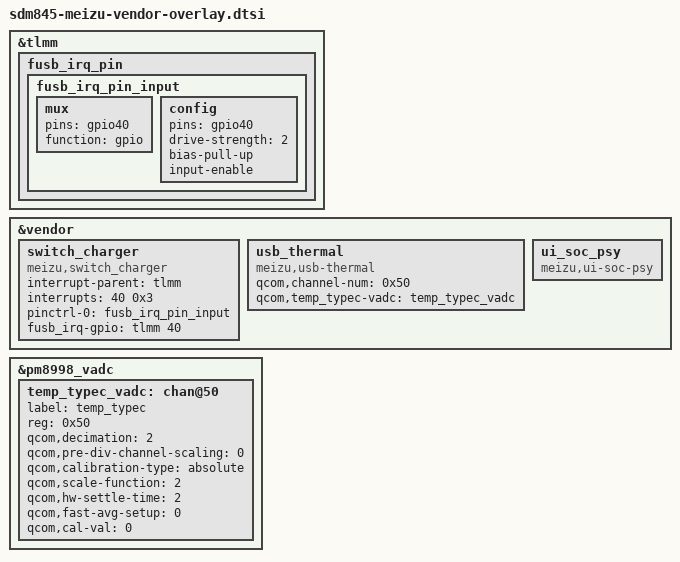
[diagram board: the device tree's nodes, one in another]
/* Copyright (c) 2022, MeizuCustoms enthusiasts
 *
 * This program is free software; you can redistribute it and/or modify
 * it under the terms of the GNU General Public License version 2 and
 * only version 2 as published by the Free Software Foundation.
 *
 * This program is distributed in the hope that it will be useful,
 * but WITHOUT ANY WARRANTY; without even the implied warranty of
 * MERCHANTABILITY or FITNESS FOR A PARTICULAR PURPOSE.  See the
 * GNU General Public License for more details.
 */

&tlmm {
    fusb_irq_pin {
        fusb_irq_pin_input: fusb_irq_pin_input {
            mux {
                pins = "gpio40";
                function = "gpio";
            };

            config {
                pins = "gpio40";
                drive-strength = <2>;
                bias-pull-up;
                input-enable;
            };
        };
    };
};

&vendor {
    switch_charger {
        compatible = "meizu,switch_charger";
        interrupt-parent = <&tlmm>;
        interrupts = <40 0x3>;
        interrupt-names = "fusb_irq";
        pinctrl-0 = <&fusb_irq_pin_input>;
        pinctrl-names = "default";
        fusb_irq-gpio = <&tlmm 40 0x0>;
    };

    usb_thermal {
        compatible = "meizu,usb-thermal";
        qcom,channel-num = <0x50>;
        qcom,temp_typec-vadc = <&temp_typec_vadc>;
    };

    ui_soc_psy {
        compatible = "meizu,ui-soc-psy";
    };
};

&pm8998_vadc {
    temp_typec_vadc: chan@50 {
        label = "temp_typec";
        reg = <0x50>;
        qcom,decimation = <2>;
        qcom,pre-div-channel-scaling = <0>;
        qcom,calibration-type = "absolute";
        qcom,scale-function = <2>;
        qcom,hw-settle-time = <2>;
        qcom,fast-avg-setup = <0>;
        qcom,cal-val = <0>;
    };
};
